# UPD70F3508 register map
Vendor: Renesas; Series: V850E2/Px4; File version: 1.0
CPU: other r0p0, little endian, no MPU, FPU, 4 interrupt priority bits
Registers are 8-bit, read-write, reset 0x0 unless marked. A register's access mark holds for its fields unless they carry their own. Offsets are from the block's base; [hi:lo] are bit positions.

## UARTH0 — Synchronous/Asynchronous Serial Interface H, instance 0
Base 0xFF5C0000
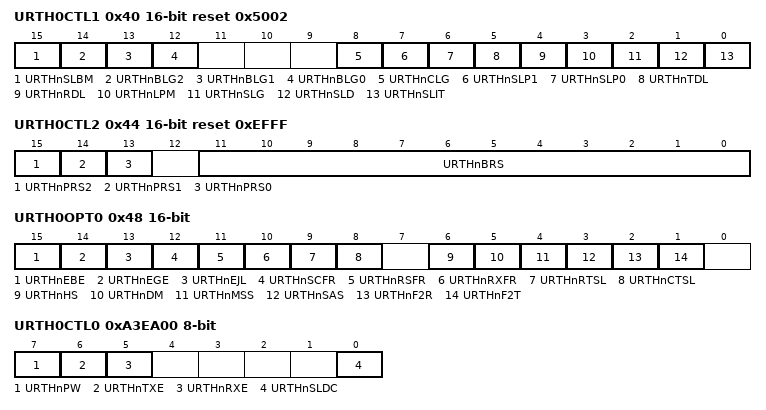
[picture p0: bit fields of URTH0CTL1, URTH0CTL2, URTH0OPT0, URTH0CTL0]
0x40 URTH0CTL1 16-bit reset 0x5002 — UARTHn Control Register 1 — data frame properties
  [15] URTHnSLBM — BF reception mode selection (0=disabled during data reception, 1=enabled)
  [14] URTHnBLG2 — BF bit length during transmission [2]
  [13] URTHnBLG1 — BF bit length during transmission [1]
  [12] URTHnBLG0 — BF bit length during transmission [0]
  [8] URTHnCLG — Bit length of transmit/receive data (0=7 bits, 1=8/9 bits)
  [7] URTHnSLP1 — Parity bit selection [1]
  [6] URTHnSLP0 — Parity bit selection [0]
  [5] URTHnTDL — Transmit data level control (0=normal, 1=inverted)
  [4] URTHnRDL — Received data level control (0=normal, 1=inverted)
  [3] URTHnLPM — Loop back mode control (0=disabled, 1=enabled)
  [2] URTHnSLG — Stop bit count for transmit (0=1 bit, 1=2 bits)
  [1] URTHnSLD — Transfer direction (0=MSB-first, 1=LSB-first)
  [0] URTHnSLIT — Transmission interrupt timing (0=at start, 1=at completion)
0x44 URTH0CTL2 16-bit reset 0xEFFF — UARTHn Control Register 2 — baud rate
  [15] URTHnPRS2 — Prescaler clock division [2]
  [14] URTHnPRS1 — Prescaler clock division [1]
  [13] URTHnPRS0 — Prescaler clock division [0]
  [11:0] URTHnBRS — Baud-rate clock division value [11:0]
0x48 URTH0OPT0 16-bit — UARTHn Option Register 0 — optional serial transfer features
  [15] URTHnEBE — Enhanced bit operation enable (0=disabled, 1=enabled)
  [14] URTHnEGE — Enhanced bit detection interrupt enable (0=disabled, 1=enabled)
  [13] URTHnEJL — Enhanced bit detection condition (0=detect 0, 1=detect 1)
  [12] URTHnSCFR — Noise filter for synchronizing clock (0=enabled, 1=disabled)
  [11] URTHnRSFR — Noise filter for handshake signal input (0=enabled, 1=disabled)
  [10] URTHnRXFR — Noise filter for received data (0=enabled, 1=disabled)
  [9] URTHnRTSL — Active level of handshake output (0=low, 1=high)
  [8] URTHnCTSL — Active level of handshake input (0=low, 1=high)
  [6] URTHnHS — Handshaking enable (0=disabled, 1=enabled)
  [5] URTHnDM — Sampling timing in clock synchronous mode (0=rising, 1=falling)
  [4] URTHnMSS — Master/slave selection in clock sync mode (0=master, 1=slave)
  [3] URTHnSAS — Operating mode (0=asynchronous, 1=synchronous)
  [2] URTHnF2R — Reception frame length (0=1 frame, 1=2 frames)
  [1] URTHnF2T — Transmission frame length (0=1 frame, 1=2 frames)
0xA3EA00 URTH0CTL0 — UARTHn Control Register 0 — basic serial-transfer control
  [7] URTHnPW — UARTHn enable (0=disabled, 1=enabled)
  [6] URTHnTXE — Transmission operation enable (0=disabled, 1=enabled)
  [5] URTHnRXE — Reception operation enable (0=disabled, 1=enabled)
  [0] URTHnSLDC — Data consistency check enable (0=disabled, 1=enabled)
0xA3EA04 URTH0OPT1 — UARTHn Option Register 1 — ID match detection enable
  [7] URTHnIDCN — ID match detection enable (0=disabled, 1=enabled)
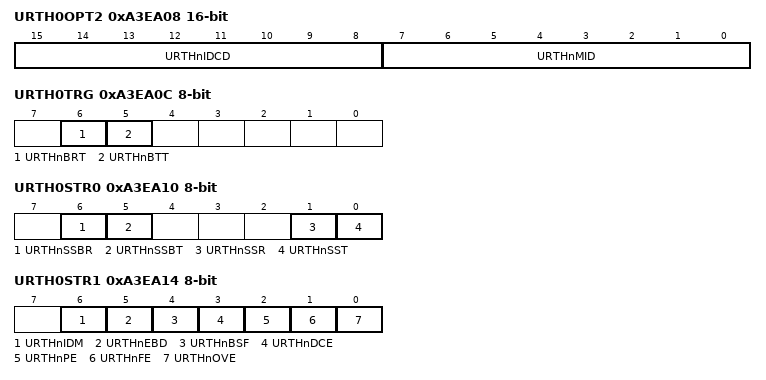
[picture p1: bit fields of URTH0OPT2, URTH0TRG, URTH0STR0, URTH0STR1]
0xA3EA08 URTH0OPT2 16-bit — UARTHn Option Register 2 — ID comparison value and mask
  [15:8] URTHnIDCD — ID value for comparison at enhanced-bit transfer [7:0]
  [7:0] URTHnMID — ID comparison mask [7:0] (1=bit not compared)
0xA3EA0C URTH0TRG — UARTHn Trigger Register — BF transmission/reception triggers
  [6] URTHnBRT — BF reception trigger (write 1 to enable BF reception)
  [5] URTHnBTT — BF transmission trigger (write 1 to trigger BF transmission)
0xA3EA10 URTH0STR0 ro — UARTHn Status Register 0 — current transmission/reception state
  [6] URTHnSSBR — BF reception enable status (0=disabled, 1=enabled/busy)
  [5] URTHnSSBT — BF transmission enable status (0=disabled, 1=enabled/busy)
  [1] URTHnSSR — Data reception state (0=not in progress, 1=in progress)
  [0] URTHnSST — Data transmission state (0=none pending, 1=pending or in progress)
0xA3EA14 URTH0STR1 ro — UARTHn Status Register 1 — transmission/reception result flags
  [6] URTHnIDM — ID value match detection flag
  [5] URTHnEBD — Enhanced bit detection flag
  [4] URTHnBSF — BF reception successful flag
  [3] URTHnDCE — Data consistency error flag
  [2] URTHnPE — Parity error flag
  [1] URTHnFE — Framing error flag
  [0] URTHnOVE — Overrun error flag
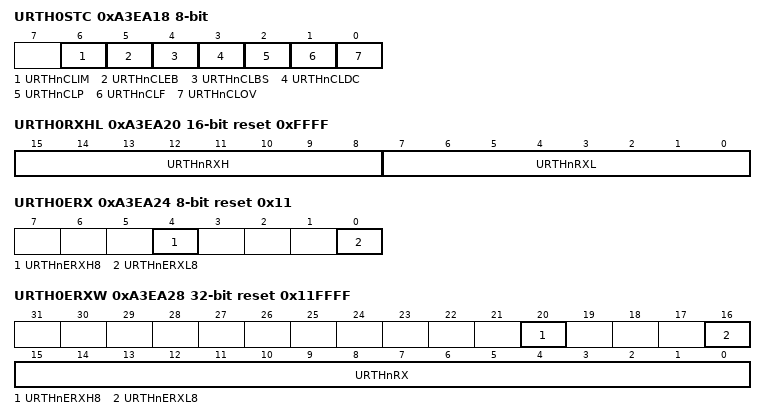
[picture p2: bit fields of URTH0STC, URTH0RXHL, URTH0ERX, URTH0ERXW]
0xA3EA18 URTH0STC — UARTHn Status Clear Register — clears STR1 status bits
  [6] URTHnCLIM — Clear URTHnIDM flag (write 1)
  [5] URTHnCLEB — Clear URTHnEBD flag (write 1)
  [4] URTHnCLBS — Clear URTHnBSF flag (write 1)
  [3] URTHnCLDC — Clear URTHnDCE flag (write 1)
  [2] URTHnCLP — Clear URTHnPE flag (write 1)
  [1] URTHnCLF — Clear URTHnFE flag (write 1)
  [0] URTHnCLOV — Clear URTHnOVE flag (write 1)
0xA3EA1C URTH0RX ro reset 0xFF — UARTHn Receive Data Register — 7/8-bit received data
  [7:0] URTHnRX — Received data [7:0]
0xA3EA20 URTH0RXHL 16-bit ro reset 0xFFFF — UARTHn Receive Data Register HL — 9-bit / 2-frame received data
  [15:8] URTHnRXH — Received data high byte [15:8]
  [7:0] URTHnRXL — Received data low byte [7:0]
0xA3EA24 URTH0ERX ro reset 0x11 — UARTHn Enhanced Bit Receive Data Register
  [4] URTHnERXH8 — Enhanced bit of high frame received data
  [0] URTHnERXL8 — Enhanced bit of low frame received data
0xA3EA28 URTH0ERXW 32-bit ro reset 0x11FFFF — UARTHn Enhanced Bit Receive Word Data Register — 32-bit combined
  [20] URTHnERXH8 — Enhanced bit of high frame received data
  [16] URTHnERXL8 — Enhanced bit of low frame received data
  [15:0] URTHnRX — Received data [15:0]
0xA3EA2C URTH0TX reset 0xFF — UARTHn Transmit Data Register — 7/8-bit transmit data
  [7:0] URTHnTX — Transmit data [7:0]
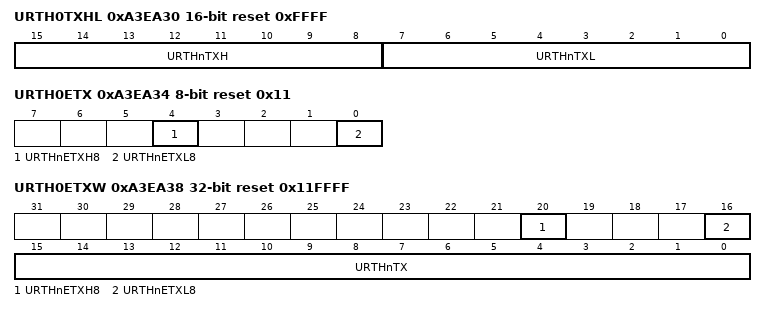
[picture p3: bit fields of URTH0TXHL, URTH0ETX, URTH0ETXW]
0xA3EA30 URTH0TXHL 16-bit reset 0xFFFF — UARTHn Transmit Data Register HL — 9-bit / 2-frame transmit data
  [15:8] URTHnTXH — Transmit data high byte [15:8]
  [7:0] URTHnTXL — Transmit data low byte [7:0]
0xA3EA34 URTH0ETX reset 0x11 — UARTHn Enhanced Bit Transmit Data Register
  [4] URTHnETXH8 — Enhanced bit for high frame transmit data
  [0] URTHnETXL8 — Enhanced bit for low frame transmit data
0xA3EA38 URTH0ETXW 32-bit reset 0x11FFFF — UARTHn Enhanced Bit Transmit Word Data Register — 32-bit combined
  [20] URTHnETXH8 — Enhanced bit for high frame transmit data
  [16] URTHnETXL8 — Enhanced bit for low frame transmit data
  [15:0] URTHnTX — Transmit data [15:0]
